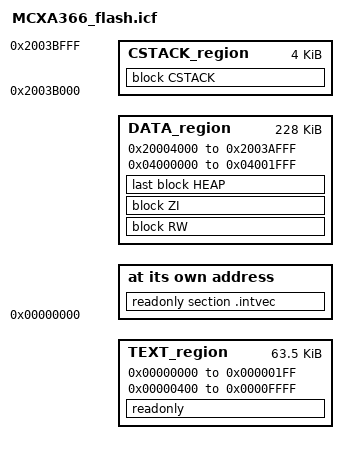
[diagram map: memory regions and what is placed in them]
/*
** ###################################################################
**     Processors:          MCXA366VLH
**                          MCXA366VLL
**                          MCXA366VLQ
**                          MCXA366VPN
**
**     Compiler:            IAR ANSI C/C++ Compiler for ARM
**     Reference manual:    MCXAP144M180FS6_RM_Rev.1_DraftC
**     Version:             rev. 1.0, 2024-03-26
**     Build:               b241119
**
**     Abstract:
**         Linker file for the IAR ANSI C/C++ Compiler for ARM
**
**     Copyright 2016 Freescale Semiconductor, Inc.
**     Copyright 2016-2026 NXP
**     SPDX-License-Identifier: BSD-3-Clause
**
**     http:                 www.nxp.com
**     mail:                 support@nxp.com
**
** ###################################################################
*/

/*
  MCUBoot region            0x000000 - 0x010000 : 64kB  (0x10000 bytes)
  Primary slot              0x010000 - 0x082000 : 456kB (0x72000 bytes)
  Secondary slot            0x082000 - 0x0F4000 : 456kB (0x72000 bytes)
  Reserved                  0x0F4000 - 0x0F6000 : 8kB   (0x02000 bytes)
  Secure installer (locked) 0x0F6000 - 0x0FE000 : 32kB  (0x08000 bytes)
  CMPA (reserved)           0x0FE000 - 0x100000 : 8kB   (0x02000 bytes)
*/

/* Stack and Heap Sizes */
if (isdefinedsymbol(__stack_size__)) {
  define symbol __size_cstack__        = __stack_size__;
} else {
  define symbol __size_cstack__        = 0x1000;
}

if (isdefinedsymbol(__heap_size__)) {
  define symbol __size_heap__          = __heap_size__;
} else {
  define symbol __size_heap__          = 0x0400;
}

/* SRAM A1,A2 are reserved for PKC */
if (isdefinedsymbol(__pkc__)) {
  define symbol __ram_offset__         = 0x4000;
} else {
  define symbol __ram_offset__         = 0;
}

define symbol m_interrupts_start               = 0x00000000;
define symbol m_interrupts_end                 = 0x000001FF;

define symbol m_text_start                     = 0x00000400;
define symbol m_text_end                       = 0x0000FFFF;

define symbol m_data_start                     = 0x20000000 + __ram_offset__;
define symbol m_data_end                       = 0x2003BFFF;

define symbol m_sramx0_start                   = 0x04000000;
define symbol m_sramx0_end                     = 0x04001FFF;

define memory mem with size = 4G;

define region TEXT_region             = mem:[from m_interrupts_start to m_interrupts_end]
                                      | mem:[from m_text_start to m_text_end];
define region DATA_region = mem:[from m_data_start to m_data_end-__size_cstack__]
                          | mem:[from m_sramx0_start to m_sramx0_end];

define region CSTACK_region = mem:[from m_data_end-__size_cstack__+1 to m_data_end];
if (isdefinedsymbol(__use_shmem__)) {
  define region rpmsg_sh_mem_region     = mem:[from rpmsg_sh_mem_start to rpmsg_sh_mem_end];
}

define block CSTACK    with alignment = 8, size = __size_cstack__   { };
define block HEAP      with alignment = 8, size = __size_heap__     { };
define block RW        { readwrite };
define block ZI        { zi };

initialize by copy { readwrite, section .textrw };

if (isdefinedsymbol(__USE_DLIB_PERTHREAD))
{
  /* Required in a multi-threaded application */
  initialize by copy with packing = none { section __DLIB_PERTHREAD };
}


place at address mem: m_interrupts_start    { readonly section .intvec };
place in TEXT_region                        { readonly };
place in DATA_region                        { block RW };
place in DATA_region                        { block ZI };
place in DATA_region                        { last block HEAP };
place in CSTACK_region                      { block CSTACK };


